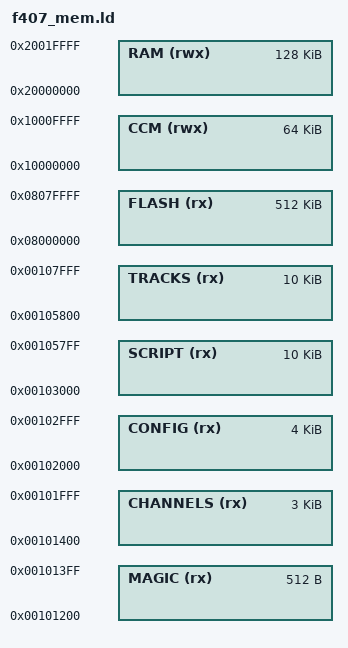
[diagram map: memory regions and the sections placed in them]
_estack = 0x20020000;

_Min_Heap_Size = 0x200;
_Min_Stack_Size = 0x200;

MEMORY
{
  FLASH 	(rx) 	: ORIGIN = 0x08000000, LENGTH = 512K
  MAGIC  	(rx) 	: ORIGIN = 0x00101200, LENGTH = 512
  CHANNELS 	(rx) 	: ORIGIN = 0x00101400, LENGTH = 3072
  CONFIG 	(rx) 	: ORIGIN = 0x00102000, LENGTH = 4096
  SCRIPT 	(rx) 	: ORIGIN = 0x00103000, LENGTH = 10240
  TRACKS 	(rx) 	: ORIGIN = 0x00105800, LENGTH = 10240  
  RAM 		(rwx) 	: ORIGIN = 0x20000000, LENGTH = 128K
  CCM 		(rwx) 	: ORIGIN = 0x10000000, LENGTH = 64K
}
